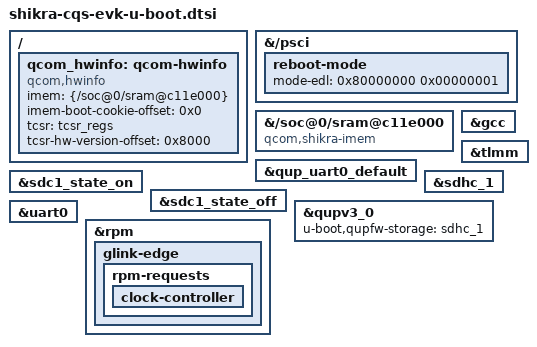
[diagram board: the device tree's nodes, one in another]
// SPDX-License-Identifier: BSD-3-Clause
/*
 * Copyright (c) 2025, Qualcomm Innovation Center, Inc. All rights reserved.
 */

/* Enter Qualcomm EDL/download mode via "reset -edl". */
&{/psci} {
	reboot-mode {
		mode-edl = <0x80000000 0x00000001>;
	};
};

/ {
	qcom_hwinfo: qcom-hwinfo {
		compatible = "qcom,hwinfo";

		imem = <&{/soc@0/sram@c11e000}>;
		imem-boot-cookie-offset = <0x0>;

		tcsr = <&tcsr_regs>;
		tcsr-hw-version-offset = <0x8000>;
	};
};

&{/soc@0/sram@c11e000} {
	compatible = "qcom,shikra-imem", "syscon", "simple-mfd";
};

/* Keep the console and QUPFW storage paths in the SPL device tree. */
&gcc {
	bootph-all;
};

&tlmm {
	bootph-all;
};

&qup_uart0_default {
	bootph-all;
};

&sdc1_state_on {
	bootph-all;
};

&sdc1_state_off {
	bootph-all;
};

&sdhc_1 {
	bootph-all;
};

&qupv3_0 {
	u-boot,qupfw-storage = <&sdhc_1>;
	bootph-all;
};

&uart0 {
	bootph-all;
};

&rpm {
	bootph-all;

	glink-edge {
		bootph-all;

		rpm-requests {
			bootph-all;

			clock-controller {
				bootph-all;
			};
		};
	};
};
